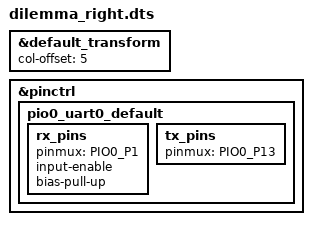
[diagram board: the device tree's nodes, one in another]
/*
 * Copyright (c) 2024 ZMK Contributors
 *
 * SPDX-License-Identifier: MIT
 */

/dts-v1/;
#include "dilemma.dtsi"

// RH has col offset of 5
&default_transform {
    col-offset = <5>;
};

&pinctrl {
    pio0_uart0_default: pio0_uart0_default {
        rx_pins {
            pinmux = <PIO0_P1>;
            input-enable;
            bias-pull-up;
        };
        tx_pins {
            pinmux = <PIO0_P13>; // TX Bodged to `QP_RST` for central half.
        };
    };
};
